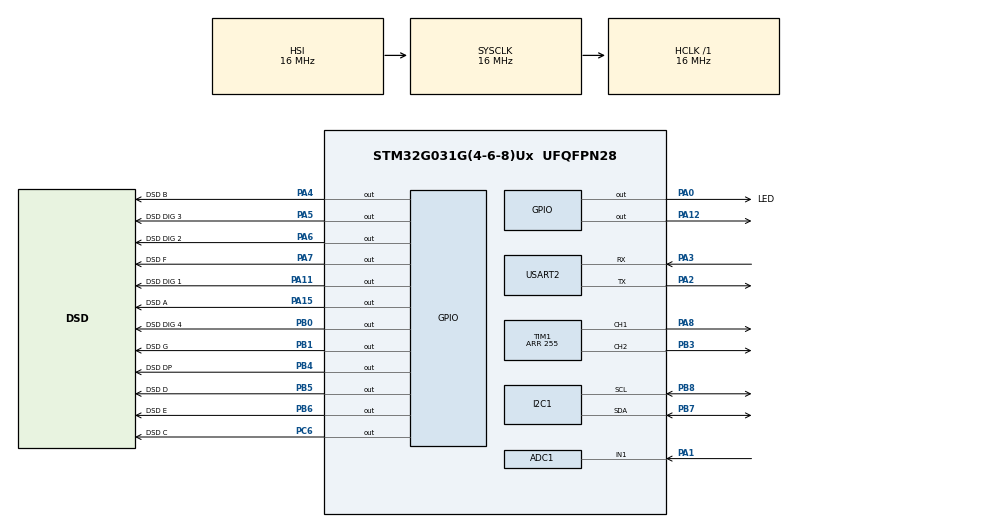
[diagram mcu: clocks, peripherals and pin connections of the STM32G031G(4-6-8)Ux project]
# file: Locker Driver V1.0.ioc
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ADC1.Channel-0\#ChannelRegularConversion=ADC_CHANNEL_1
ADC1.NbrOfConversionFlag=1
ADC1.Rank-0\#ChannelRegularConversion=1
ADC1.SamplingTime-0\#ChannelRegularConversion=ADC_SAMPLINGTIME_COMMON_1
ADC1.SelectedChannel=ADC_CHANNEL_1
ADC1.master=1
I2C1.OwnAddress=0x38
I2C1.Timing=0x00503D58
IWDG.Prescaler=IWDG_PRESCALER_16
IWDG.Window=2999
Mcu.Family=STM32G0
Mcu.Name=STM32G031G(4-6-8)Ux
Mcu.Package=UFQFPN28
NVIC.I2C1_IRQn=true\:0\:0\:false\:false\:true\:true\:true\:true
NVIC.TIM14_IRQn=true\:0\:0\:false\:false\:true\:true\:true\:true
PA0.GPIO_Label=LED
PA0.Signal=GPIO_Output
PA1.Mode=IN1
PA1.Signal=ADC1_IN1
PA11\ [PA9].GPIO_Label=DSD DIG 1
PA11\ [PA9].GPIO_ModeDefaultOutputPP=GPIO_MODE_OUTPUT_PP
PA11\ [PA9].GPIO_PuPd=GPIO_NOPULL
PA11\ [PA9].GPIO_Speed=GPIO_SPEED_FREQ_HIGH
PA11\ [PA9].Signal=GPIO_Output
PA12\ [PA10].GPIO_Speed=GPIO_SPEED_FREQ_HIGH
PA12\ [PA10].Signal=GPIO_Output
PA13.Mode=Serial_Wire
PA13.Signal=SYS_SWDIO
PA14-BOOT0.Mode=Serial_Wire
PA14-BOOT0.Signal=SYS_SWCLK
PA15.GPIO_Label=DSD A
PA15.GPIO_ModeDefaultOutputPP=GPIO_MODE_OUTPUT_OD
PA15.GPIO_PuPd=GPIO_NOPULL
PA15.GPIO_Speed=GPIO_SPEED_FREQ_HIGH
PA15.PinState=GPIO_PIN_SET
PA15.Signal=GPIO_Output
PA2.Mode=Asynchronous
PA2.Signal=USART2_TX
PA3.Mode=Asynchronous
PA3.Signal=USART2_RX
PA4.GPIO_Label=DSD B
PA4.GPIO_ModeDefaultOutputPP=GPIO_MODE_OUTPUT_OD
PA4.GPIO_PuPd=GPIO_NOPULL
PA4.GPIO_Speed=GPIO_SPEED_FREQ_HIGH
PA4.PinState=GPIO_PIN_SET
PA4.Signal=GPIO_Output
PA5.GPIO_Label=DSD DIG 3
PA5.GPIO_ModeDefaultOutputPP=GPIO_MODE_OUTPUT_PP
PA5.GPIO_PuPd=GPIO_NOPULL
PA5.GPIO_Speed=GPIO_SPEED_FREQ_HIGH
PA5.Signal=GPIO_Output
PA6.GPIO_Label=DSD DIG 2
PA6.GPIO_ModeDefaultOutputPP=GPIO_MODE_OUTPUT_PP
PA6.GPIO_PuPd=GPIO_NOPULL
PA6.GPIO_Speed=GPIO_SPEED_FREQ_HIGH
PA6.Signal=GPIO_Output
PA7.GPIO_Label=DSD F
PA7.GPIO_ModeDefaultOutputPP=GPIO_MODE_OUTPUT_OD
PA7.GPIO_PuPd=GPIO_NOPULL
PA7.GPIO_Speed=GPIO_SPEED_FREQ_HIGH
PA7.PinState=GPIO_PIN_SET
PA7.Signal=GPIO_Output
PA8.Signal=S_TIM1_CH1
PB0.GPIO_Label=DSD DIG 4
PB0.GPIO_ModeDefaultOutputPP=GPIO_MODE_OUTPUT_PP
PB0.GPIO_PuPd=GPIO_NOPULL
PB0.GPIO_Speed=GPIO_SPEED_FREQ_HIGH
PB0.Signal=GPIO_Output
PB1.GPIO_Label=DSD G
PB1.GPIO_ModeDefaultOutputPP=GPIO_MODE_OUTPUT_OD
PB1.GPIO_PuPd=GPIO_NOPULL
PB1.GPIO_Speed=GPIO_SPEED_FREQ_HIGH
PB1.PinState=GPIO_PIN_SET
PB1.Signal=GPIO_Output
PB3.Signal=S_TIM1_CH2
PB4.GPIO_Label=DSD DP
PB4.GPIO_ModeDefaultOutputPP=GPIO_MODE_OUTPUT_OD
PB4.GPIO_PuPd=GPIO_NOPULL
PB4.GPIO_Speed=GPIO_SPEED_FREQ_HIGH
PB4.PinState=GPIO_PIN_SET
PB4.Signal=GPIO_Output
PB5.GPIO_Label=DSD D
PB5.GPIO_ModeDefaultOutputPP=GPIO_MODE_OUTPUT_OD
PB5.GPIO_PuPd=GPIO_NOPULL
PB5.GPIO_Speed=GPIO_SPEED_FREQ_HIGH
PB5.PinState=GPIO_PIN_SET
PB5.Signal=GPIO_Output
PB6.GPIO_Label=DSD E
PB6.GPIO_ModeDefaultOutputPP=GPIO_MODE_OUTPUT_OD
PB6.GPIO_PuPd=GPIO_PULLUP
PB6.GPIO_Speed=GPIO_SPEED_FREQ_HIGH
PB6.PinState=GPIO_PIN_SET
PB6.Signal=GPIO_Output
PB7.Mode=I2C
PB7.Signal=I2C1_SDA
PB8.Mode=I2C
PB8.Signal=I2C1_SCL
PC6.GPIO_Label=DSD C
PC6.GPIO_ModeDefaultOutputPP=GPIO_MODE_OUTPUT_OD
PC6.GPIO_PuPd=GPIO_NOPULL
PC6.GPIO_Speed=GPIO_SPEED_FREQ_HIGH
PC6.PinState=GPIO_PIN_SET
PC6.Signal=GPIO_Output
ProjectManager.HeapSize=0x200
ProjectManager.StackSize=0x400
ProjectManager.TargetToolchain=STM32CubeIDE
RCC.AHBFreq_Value=16000000
RCC.CortexFreq_Value=16000000
RCC.EXTERNAL_CLOCK_VALUE=12288000
RCC.HCLKFreq_Value=16000000
RCC.HSE_VALUE=8000000
RCC.HSI_VALUE=16000000
RCC.LSE_VALUE=32768
RCC.SYSCLKFreq_VALUE=16000000
RCC.VCOOutputFreq_Value=128000000
SH.S_TIM1_CH1.0=TIM1_CH1,PWM Generation1 CH1
SH.S_TIM1_CH2.0=TIM1_CH2,PWM Generation2 CH2
TIM1.AutoReloadPreload=TIM_AUTORELOAD_PRELOAD_ENABLE
TIM1.Channel-PWM\ Generation1\ CH1=TIM_CHANNEL_1
TIM1.Channel-PWM\ Generation2\ CH2=TIM_CHANNEL_2
TIM1.Period=255
TIM14.Period=100
TIM14.Prescaler=15
USART2.VirtualMode-Asynchronous=VM_ASYNC
VP_IWDG_VS_IWDG.Mode=IWDG_Activate
VP_TIM14_VS_ClockSourceINT.Mode=Enable_Timer
VP_TIM1_VS_ClockSourceINT.Mode=Internal
board=custom

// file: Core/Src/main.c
/* USER CODE BEGIN Header */
/**
  ******************************************************************************
  * @file           : main.c
  * @brief          : Main program body
  ******************************************************************************
  */
/* USER CODE END Header */
#include "main.h"

/* USER CODE BEGIN Includes */
#include <stdint.h>
#include "app.h"
#include "rgb.h"
/* USER CODE END Includes */

ADC_HandleTypeDef hadc1;

I2C_HandleTypeDef hi2c1;

IWDG_HandleTypeDef hiwdg;

TIM_HandleTypeDef htim1;
TIM_HandleTypeDef htim14;

UART_HandleTypeDef huart2;

void SystemClock_Config(void);
static void MX_GPIO_Init(void);
static void MX_ADC1_Init(void);
static void MX_I2C1_Init(void);
static void MX_TIM1_Init(void);
static void MX_USART2_UART_Init(void);
static void MX_TIM14_Init(void);
static void MX_IWDG_Init(void);

int main(void)
{

  /* MCU Configuration--------------------------------------------------------*/

  /* Reset of all peripherals, Initializes the Flash interface and the Systick. */
  HAL_Init();

  /* Configure the system clock */
  SystemClock_Config();

  /* Initialize all configured peripherals */
  MX_GPIO_Init();
  MX_ADC1_Init();
  MX_I2C1_Init();
  MX_TIM1_Init();
  MX_USART2_UART_Init();
  MX_TIM14_Init();
  MX_IWDG_Init();
  /* USER CODE BEGIN 2 */
  app_init();

  /* USER CODE END 2 */

  /* Infinite loop */
  while (1)
  {

    /* USER CODE BEGIN 3 */
	  app_loop();

  }
  /* USER CODE END 3 */
}

void SystemClock_Config(void)
{
  RCC_OscInitTypeDef RCC_OscInitStruct = {0};
  RCC_ClkInitTypeDef RCC_ClkInitStruct = {0};

  /** Configure the main internal regulator output voltage
  */
  HAL_PWREx_ControlVoltageScaling(PWR_REGULATOR_VOLTAGE_SCALE1);

  /** Initializes the RCC Oscillators according to the specified parameters
  * in the RCC_OscInitTypeDef structure.
  */
  RCC_OscInitStruct.OscillatorType = RCC_OSCILLATORTYPE_HSI|RCC_OSCILLATORTYPE_LSI;
  RCC_OscInitStruct.HSIState = RCC_HSI_ON;
  RCC_OscInitStruct.HSIDiv = RCC_HSI_DIV1;
  RCC_OscInitStruct.HSICalibrationValue = RCC_HSICALIBRATION_DEFAULT;
  RCC_OscInitStruct.LSIState = RCC_LSI_ON;
  RCC_OscInitStruct.PLL.PLLState = RCC_PLL_NONE;
  if (HAL_RCC_OscConfig(&RCC_OscInitStruct) != HAL_OK)
  {
    Error_Handler();
  }

  /** Initializes the CPU, AHB and APB buses clocks
  */
  RCC_ClkInitStruct.ClockType = RCC_CLOCKTYPE_HCLK|RCC_CLOCKTYPE_SYSCLK
                              |RCC_CLOCKTYPE_PCLK1;
  RCC_ClkInitStruct.SYSCLKSource = RCC_SYSCLKSOURCE_HSI;
  RCC_ClkInitStruct.AHBCLKDivider = RCC_SYSCLK_DIV1;
  RCC_ClkInitStruct.APB1CLKDivider = RCC_HCLK_DIV1;

  if (HAL_RCC_ClockConfig(&RCC_ClkInitStruct, FLASH_LATENCY_0) != HAL_OK)
  {
    Error_Handler();
  }
}

static void MX_ADC1_Init(void)
{

  ADC_ChannelConfTypeDef sConfig = {0};

  /** Configure the global features of the ADC (Clock, Resolution, Data Alignment and number of conversion)
  */
  hadc1.Instance = ADC1;
  hadc1.Init.ClockPrescaler = ADC_CLOCK_SYNC_PCLK_DIV2;
  hadc1.Init.Resolution = ADC_RESOLUTION_12B;
  hadc1.Init.DataAlign = ADC_DATAALIGN_RIGHT;
  hadc1.Init.ScanConvMode = ADC_SCAN_DISABLE;
  hadc1.Init.EOCSelection = ADC_EOC_SINGLE_CONV;
  hadc1.Init.LowPowerAutoWait = DISABLE;
  hadc1.Init.LowPowerAutoPowerOff = DISABLE;
  hadc1.Init.ContinuousConvMode = DISABLE;
  hadc1.Init.NbrOfConversion = 1;
  hadc1.Init.DiscontinuousConvMode = DISABLE;
  hadc1.Init.ExternalTrigConv = ADC_SOFTWARE_START;
  hadc1.Init.ExternalTrigConvEdge = ADC_EXTERNALTRIGCONVEDGE_NONE;
  hadc1.Init.DMAContinuousRequests = DISABLE;
  hadc1.Init.Overrun = ADC_OVR_DATA_PRESERVED;
  hadc1.Init.SamplingTimeCommon1 = ADC_SAMPLETIME_1CYCLE_5;
  hadc1.Init.SamplingTimeCommon2 = ADC_SAMPLETIME_1CYCLE_5;
  hadc1.Init.OversamplingMode = DISABLE;
  hadc1.Init.TriggerFrequencyMode = ADC_TRIGGER_FREQ_HIGH;
  if (HAL_ADC_Init(&hadc1) != HAL_OK)
  {
    Error_Handler();
  }

  /** Configure Regular Channel
  */
  sConfig.Channel = ADC_CHANNEL_1;
  sConfig.Rank = ADC_REGULAR_RANK_1;
  sConfig.SamplingTime = ADC_SAMPLINGTIME_COMMON_1;
  if (HAL_ADC_ConfigChannel(&hadc1, &sConfig) != HAL_OK)
  {
    Error_Handler();
  }

}

static void MX_I2C1_Init(void)
{

  hi2c1.Instance = I2C1;
  hi2c1.Init.Timing = 0x00503D58;
  hi2c1.Init.OwnAddress1 = 112;
  hi2c1.Init.AddressingMode = I2C_ADDRESSINGMODE_7BIT;
  hi2c1.Init.DualAddressMode = I2C_DUALADDRESS_DISABLE;
  hi2c1.Init.OwnAddress2 = 0;
  hi2c1.Init.OwnAddress2Masks = I2C_OA2_NOMASK;
  hi2c1.Init.GeneralCallMode = I2C_GENERALCALL_DISABLE;
  hi2c1.Init.NoStretchMode = I2C_NOSTRETCH_DISABLE;
  if (HAL_I2C_Init(&hi2c1) != HAL_OK)
  {
    Error_Handler();
  }

  /** Configure Analogue filter
  */
  if (HAL_I2CEx_ConfigAnalogFilter(&hi2c1, I2C_ANALOGFILTER_ENABLE) != HAL_OK)
  {
    Error_Handler();
  }

  /** Configure Digital filter
  */
  if (HAL_I2CEx_ConfigDigitalFilter(&hi2c1, 0) != HAL_OK)
  {
    Error_Handler();
  }

}

static void MX_IWDG_Init(void)
{

  hiwdg.Instance = IWDG;
  hiwdg.Init.Prescaler = IWDG_PRESCALER_16;
  hiwdg.Init.Window = 2999;
  hiwdg.Init.Reload = 4095;
  if (HAL_IWDG_Init(&hiwdg) != HAL_OK)
  {
    Error_Handler();
  }

}

static void MX_TIM1_Init(void)
{

  TIM_ClockConfigTypeDef sClockSourceConfig = {0};
  TIM_MasterConfigTypeDef sMasterConfig = {0};
  TIM_OC_InitTypeDef sConfigOC = {0};
  TIM_BreakDeadTimeConfigTypeDef sBreakDeadTimeConfig = {0};

  htim1.Instance = TIM1;
  htim1.Init.Prescaler = 0;
  htim1.Init.CounterMode = TIM_COUNTERMODE_UP;
  htim1.Init.Period = 255;
  htim1.Init.ClockDivision = TIM_CLOCKDIVISION_DIV1;
  htim1.Init.RepetitionCounter = 0;
  htim1.Init.AutoReloadPreload = TIM_AUTORELOAD_PRELOAD_ENABLE;
  if (HAL_TIM_Base_Init(&htim1) != HAL_OK)
  {
    Error_Handler();
  }
  sClockSourceConfig.ClockSource = TIM_CLOCKSOURCE_INTERNAL;
  if (HAL_TIM_ConfigClockSource(&htim1, &sClockSourceConfig) != HAL_OK)
  {
    Error_Handler();
  }
  if (HAL_TIM_PWM_Init(&htim1) != HAL_OK)
  {
    Error_Handler();
  }
  sMasterConfig.MasterOutputTrigger = TIM_TRGO_RESET;
  sMasterConfig.MasterOutputTrigger2 = TIM_TRGO2_RESET;
  sMasterConfig.MasterSlaveMode = TIM_MASTERSLAVEMODE_DISABLE;
  if (HAL_TIMEx_MasterConfigSynchronization(&htim1, &sMasterConfig) != HAL_OK)
  {
    Error_Handler();
  }
  sConfigOC.OCMode = TIM_OCMODE_PWM1;
  sConfigOC.Pulse = 0;
  sConfigOC.OCPolarity = TIM_OCPOLARITY_HIGH;
  sConfigOC.OCNPolarity = TIM_OCNPOLARITY_HIGH;
  sConfigOC.OCFastMode = TIM_OCFAST_DISABLE;
  sConfigOC.OCIdleState = TIM_OCIDLESTATE_RESET;
  sConfigOC.OCNIdleState = TIM_OCNIDLESTATE_RESET;
  if (HAL_TIM_PWM_ConfigChannel(&htim1, &sConfigOC, TIM_CHANNEL_1) != HAL_OK)
  {
    Error_Handler();
  }
  if (HAL_TIM_PWM_ConfigChannel(&htim1, &sConfigOC, TIM_CHANNEL_2) != HAL_OK)
  {
    Error_Handler();
  }
  sBreakDeadTimeConfig.OffStateRunMode = TIM_OSSR_DISABLE;
  sBreakDeadTimeConfig.OffStateIDLEMode = TIM_OSSI_DISABLE;
  sBreakDeadTimeConfig.LockLevel = TIM_LOCKLEVEL_OFF;
  sBreakDeadTimeConfig.DeadTime = 0;
  sBreakDeadTimeConfig.BreakState = TIM_BREAK_DISABLE;
  sBreakDeadTimeConfig.BreakPolarity = TIM_BREAKPOLARITY_HIGH;
  sBreakDeadTimeConfig.BreakFilter = 0;
  sBreakDeadTimeConfig.BreakAFMode = TIM_BREAK_AFMODE_INPUT;
  sBreakDeadTimeConfig.Break2State = TIM_BREAK2_DISABLE;
  sBreakDeadTimeConfig.Break2Polarity = TIM_BREAK2POLARITY_HIGH;
  sBreakDeadTimeConfig.Break2Filter = 0;
  sBreakDeadTimeConfig.Break2AFMode = TIM_BREAK_AFMODE_INPUT;
  sBreakDeadTimeConfig.AutomaticOutput = TIM_AUTOMATICOUTPUT_DISABLE;
  if (HAL_TIMEx_ConfigBreakDeadTime(&htim1, &sBreakDeadTimeConfig) != HAL_OK)
  {
    Error_Handler();
  }
  HAL_TIM_MspPostInit(&htim1);

}

static void MX_TIM14_Init(void)
{

  htim14.Instance = TIM14;
  htim14.Init.Prescaler = 15;
  htim14.Init.CounterMode = TIM_COUNTERMODE_UP;
  htim14.Init.Period = 100;
  htim14.Init.ClockDivision = TIM_CLOCKDIVISION_DIV1;
  htim14.Init.AutoReloadPreload = TIM_AUTORELOAD_PRELOAD_DISABLE;
  if (HAL_TIM_Base_Init(&htim14) != HAL_OK)
  {
    Error_Handler();
  }

}

static void MX_USART2_UART_Init(void)
{

  huart2.Instance = USART2;
  huart2.Init.BaudRate = 115200;
  huart2.Init.WordLength = UART_WORDLENGTH_8B;
  huart2.Init.StopBits = UART_STOPBITS_1;
  huart2.Init.Parity = UART_PARITY_NONE;
  huart2.Init.Mode = UART_MODE_TX_RX;
  huart2.Init.HwFlowCtl = UART_HWCONTROL_NONE;
  huart2.Init.OverSampling = UART_OVERSAMPLING_16;
  huart2.Init.OneBitSampling = UART_ONE_BIT_SAMPLE_DISABLE;
  huart2.Init.ClockPrescaler = UART_PRESCALER_DIV1;
  huart2.AdvancedInit.AdvFeatureInit = UART_ADVFEATURE_NO_INIT;
  if (HAL_UART_Init(&huart2) != HAL_OK)
  {
    Error_Handler();
  }

}

static void MX_GPIO_Init(void)
{
  GPIO_InitTypeDef GPIO_InitStruct = {0};

  /* GPIO Ports Clock Enable */
  __HAL_RCC_GPIOA_CLK_ENABLE();
  __HAL_RCC_GPIOB_CLK_ENABLE();
  __HAL_RCC_GPIOC_CLK_ENABLE();

  /*Configure GPIO pin Output Level */
  HAL_GPIO_WritePin(GPIOA, LED_Pin|DSD_DIG_3_Pin|DSD_DIG_2_Pin|DSD_DIG_1_Pin
                          |GPIO_PIN_12, GPIO_PIN_RESET);

  /*Configure GPIO pin Output Level */
  HAL_GPIO_WritePin(GPIOA, DSD_B_Pin|DSD_F_Pin|DSD_A_Pin, GPIO_PIN_SET);

  /*Configure GPIO pin Output Level */
  HAL_GPIO_WritePin(DSD_DIG_4_GPIO_Port, DSD_DIG_4_Pin, GPIO_PIN_RESET);

  /*Configure GPIO pin Output Level */
  HAL_GPIO_WritePin(GPIOB, DSD_G_Pin|DSD_DP_Pin|DSD_D_Pin|DSD_E_Pin, GPIO_PIN_SET);

  /*Configure GPIO pin Output Level */
  HAL_GPIO_WritePin(DSD_C_GPIO_Port, DSD_C_Pin, GPIO_PIN_SET);

  /*Configure GPIO pin : LED_Pin */
  GPIO_InitStruct.Pin = LED_Pin;
  GPIO_InitStruct.Mode = GPIO_MODE_OUTPUT_PP;
  GPIO_InitStruct.Pull = GPIO_NOPULL;
  GPIO_InitStruct.Speed = GPIO_SPEED_FREQ_LOW;
  HAL_GPIO_Init(LED_GPIO_Port, &GPIO_InitStruct);

  /*Configure GPIO pins : DSD_B_Pin DSD_F_Pin DSD_A_Pin */
  GPIO_InitStruct.Pin = DSD_B_Pin|DSD_F_Pin|DSD_A_Pin;
  GPIO_InitStruct.Mode = GPIO_MODE_OUTPUT_OD;
  GPIO_InitStruct.Pull = GPIO_NOPULL;
  GPIO_InitStruct.Speed = GPIO_SPEED_FREQ_HIGH;
  HAL_GPIO_Init(GPIOA, &GPIO_InitStruct);

  /*Configure GPIO pins : DSD_DIG_3_Pin DSD_DIG_2_Pin DSD_DIG_1_Pin PA12 */
  GPIO_InitStruct.Pin = DSD_DIG_3_Pin|DSD_DIG_2_Pin|DSD_DIG_1_Pin|GPIO_PIN_12;
  GPIO_InitStruct.Mode = GPIO_MODE_OUTPUT_PP;
  GPIO_InitStruct.Pull = GPIO_NOPULL;
  GPIO_InitStruct.Speed = GPIO_SPEED_FREQ_HIGH;
  HAL_GPIO_Init(GPIOA, &GPIO_InitStruct);

  /*Configure GPIO pin : DSD_DIG_4_Pin */
  GPIO_InitStruct.Pin = DSD_DIG_4_Pin;
  GPIO_InitStruct.Mode = GPIO_MODE_OUTPUT_PP;
  GPIO_InitStruct.Pull = GPIO_NOPULL;
  GPIO_InitStruct.Speed = GPIO_SPEED_FREQ_HIGH;
  HAL_GPIO_Init(DSD_DIG_4_GPIO_Port, &GPIO_InitStruct);

  /*Configure GPIO pins : DSD_G_Pin DSD_DP_Pin DSD_D_Pin */
  GPIO_InitStruct.Pin = DSD_G_Pin|DSD_DP_Pin|DSD_D_Pin;
  GPIO_InitStruct.Mode = GPIO_MODE_OUTPUT_OD;
  GPIO_InitStruct.Pull = GPIO_NOPULL;
  GPIO_InitStruct.Speed = GPIO_SPEED_FREQ_HIGH;
  HAL_GPIO_Init(GPIOB, &GPIO_InitStruct);

  /*Configure GPIO pin : DSD_C_Pin */
  GPIO_InitStruct.Pin = DSD_C_Pin;
  GPIO_InitStruct.Mode = GPIO_MODE_OUTPUT_OD;
  GPIO_InitStruct.Pull = GPIO_NOPULL;
  GPIO_InitStruct.Speed = GPIO_SPEED_FREQ_HIGH;
  HAL_GPIO_Init(DSD_C_GPIO_Port, &GPIO_InitStruct);

  /*Configure GPIO pin : DSD_E_Pin */
  GPIO_InitStruct.Pin = DSD_E_Pin;
  GPIO_InitStruct.Mode = GPIO_MODE_OUTPUT_OD;
  GPIO_InitStruct.Pull = GPIO_PULLUP;
  GPIO_InitStruct.Speed = GPIO_SPEED_FREQ_HIGH;
  HAL_GPIO_Init(DSD_E_GPIO_Port, &GPIO_InitStruct);

}

/* USER CODE BEGIN 4 */

void HAL_TIM_PeriodElapsedCallback(TIM_HandleTypeDef *htim)
{
    rgb_tim_period_elapsed_callback(htim);
}

/* USER CODE END 4 */

void Error_Handler(void)
{
  __disable_irq();
  while (1)
  {
  }
}
